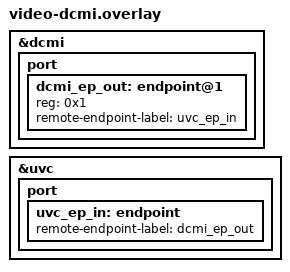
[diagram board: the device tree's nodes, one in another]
/*
 * Copyright (c) 2025 tinyVision.ai Inc.
 *
 * SPDX-License-Identifier: Apache-2.0
 */

&dcmi {
	port {
		#address-cells = <1>;
		#size-cells = <0>;

		dcmi_ep_out: endpoint@1 {
			reg = <0x1>;
			remote-endpoint-label = "uvc_ep_in";
		};
	};
};

&uvc {
	port {
		uvc_ep_in: endpoint {
			remote-endpoint-label = "dcmi_ep_out";
		};
	};
};
